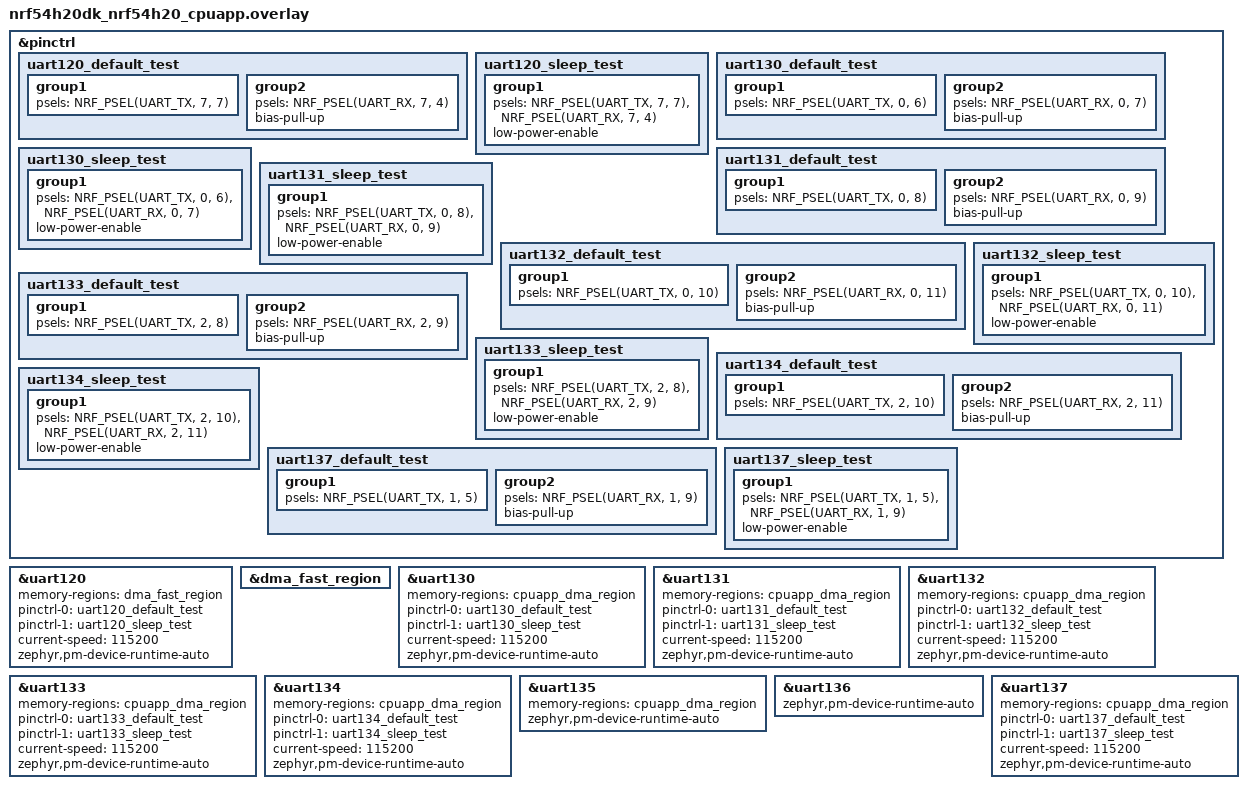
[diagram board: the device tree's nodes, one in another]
/*
 * Copyright (c) 2025 Nordic Semiconductor ASA
 *
 * SPDX-License-Identifier: LicenseRef-Nordic-5-Clause
 */

&pinctrl {
	uart120_default_test: uart120_default_test {
		group1 {
			psels = <NRF_PSEL(UART_TX, 7, 7)>;
		};

		group2 {
			psels = <NRF_PSEL(UART_RX, 7, 4)>;
			bias-pull-up;
		};
	};

	uart120_sleep_test: uart120_sleep_test {
		group1 {
			psels = <NRF_PSEL(UART_TX, 7, 7)>,
				<NRF_PSEL(UART_RX, 7, 4)>;
			low-power-enable;
		};
	};

	uart130_default_test: uart130_default_test {
		group1 {
			psels = <NRF_PSEL(UART_TX, 0, 6)>;
		};

		group2 {
			psels = <NRF_PSEL(UART_RX, 0, 7)>;
			bias-pull-up;
		};
	};

	uart130_sleep_test: uart130_sleep_test {
		group1 {
			psels = <NRF_PSEL(UART_TX, 0, 6)>,
				<NRF_PSEL(UART_RX, 0, 7)>;
			low-power-enable;
		};
	};

	uart131_default_test: uart131_default_test {
		group1 {
			psels = <NRF_PSEL(UART_TX, 0, 8)>;
		};

		group2 {
			psels = <NRF_PSEL(UART_RX, 0, 9)>;
			bias-pull-up;
		};
	};

	uart131_sleep_test: uart131_sleep_test {
		group1 {
			psels = <NRF_PSEL(UART_TX, 0, 8)>,
				<NRF_PSEL(UART_RX, 0, 9)>;
			low-power-enable;
		};
	};

	uart132_default_test: uart132_default_test {
		group1 {
			psels = <NRF_PSEL(UART_TX, 0, 10)>;
		};

		group2 {
			psels = <NRF_PSEL(UART_RX, 0, 11)>;
			bias-pull-up;
		};
	};

	uart132_sleep_test: uart132_sleep_test {
		group1 {
			psels = <NRF_PSEL(UART_TX, 0, 10)>,
				<NRF_PSEL(UART_RX, 0, 11)>;
			low-power-enable;
		};
	};

	uart133_default_test: uart133_default_test {
		group1 {
			psels = <NRF_PSEL(UART_TX, 2, 8)>;
		};

		group2 {
			psels = <NRF_PSEL(UART_RX, 2, 9)>;
			bias-pull-up;
		};
	};

	uart133_sleep_test: uart133_sleep_test {
		group1 {
			psels = <NRF_PSEL(UART_TX, 2, 8)>,
				<NRF_PSEL(UART_RX, 2, 9)>;
			low-power-enable;
		};
	};

	uart134_default_test: uart134_default_test {
		group1 {
			psels = <NRF_PSEL(UART_TX, 2, 10)>;
		};

		group2 {
			psels = <NRF_PSEL(UART_RX, 2, 11)>;
			bias-pull-up;
		};
	};

	uart134_sleep_test: uart134_sleep_test {
		group1 {
			psels = <NRF_PSEL(UART_TX, 2, 10)>,
				<NRF_PSEL(UART_RX, 2, 11)>;
			low-power-enable;
		};
	};

	/* use default pinctrl for uart135 */

	/* use default pinctrl for uart136 */

	uart137_default_test: uart137_default_test {
		group1 {
			psels = <NRF_PSEL(UART_TX, 1, 5)>;
		};

		group2 {
			psels = <NRF_PSEL(UART_RX, 1, 9)>;
			bias-pull-up;
		};
	};

	uart137_sleep_test: uart137_sleep_test {
		group1 {
			psels = <NRF_PSEL(UART_TX, 1, 5)>,
				<NRF_PSEL(UART_RX, 1, 9)>;
			low-power-enable;
		};
	};
};

&uart120 {
	status = "okay";
	memory-regions = <&dma_fast_region>;
	pinctrl-0 = <&uart120_default_test>;
	pinctrl-1 = <&uart120_sleep_test>;
	pinctrl-names = "default", "sleep";
	current-speed = <115200>;
	zephyr,pm-device-runtime-auto;
};

&dma_fast_region {
	status = "okay";
};

&uart130 {
	status = "okay";
	memory-regions = <&cpuapp_dma_region>;
	pinctrl-0 = <&uart130_default_test>;
	pinctrl-1 = <&uart130_sleep_test>;
	pinctrl-names = "default", "sleep";
	current-speed = <115200>;
	zephyr,pm-device-runtime-auto;
};

&uart131 {
	status = "okay";
	memory-regions = <&cpuapp_dma_region>;
	pinctrl-0 = <&uart131_default_test>;
	pinctrl-1 = <&uart131_sleep_test>;
	pinctrl-names = "default", "sleep";
	current-speed = <115200>;
	zephyr,pm-device-runtime-auto;
};

&uart132 {
	status = "okay";
	memory-regions = <&cpuapp_dma_region>;
	pinctrl-0 = <&uart132_default_test>;
	pinctrl-1 = <&uart132_sleep_test>;
	pinctrl-names = "default", "sleep";
	current-speed = <115200>;
	zephyr,pm-device-runtime-auto;
};

&uart133 {
	status = "okay";
	memory-regions = <&cpuapp_dma_region>;
	pinctrl-0 = <&uart133_default_test>;
	pinctrl-1 = <&uart133_sleep_test>;
	pinctrl-names = "default", "sleep";
	current-speed = <115200>;
	zephyr,pm-device-runtime-auto;
};

&uart134 {
	status = "okay";
	memory-regions = <&cpuapp_dma_region>;
	pinctrl-0 = <&uart134_default_test>;
	pinctrl-1 = <&uart134_sleep_test>;
	pinctrl-names = "default", "sleep";
	current-speed = <115200>;
	zephyr,pm-device-runtime-auto;
};

&uart135 {
	status = "okay";
	memory-regions = <&cpuapp_dma_region>;
	zephyr,pm-device-runtime-auto;
};

&uart136 {
	status = "okay";
	zephyr,pm-device-runtime-auto;
};

&uart137 {
	status = "okay";
	memory-regions = <&cpuapp_dma_region>;
	pinctrl-0 = <&uart137_default_test>;
	pinctrl-1 = <&uart137_sleep_test>;
	pinctrl-names = "default", "sleep";
	current-speed = <115200>;
	zephyr,pm-device-runtime-auto;
};
